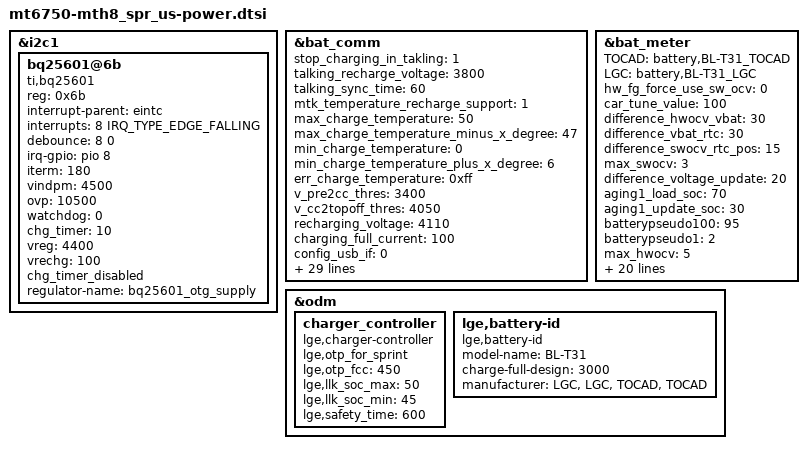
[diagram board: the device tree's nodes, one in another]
/*
 * LG Electronics TH8 power device tree source
 *
 * Copyright (c) 2017 LG Electronics Co., Ltd.
 *              http://www.lge.com
 *
 */

#include "../battery-BL-T31.dtsi"

/* Power */
&i2c1 {
	bq25601@6b {
		status = "okay";
		compatible = "ti,bq25601";
		reg = <0x6b>;

		interrupt-parent = <&eintc>;
		interrupts = <8 IRQ_TYPE_EDGE_FALLING>;
		debounce = <8 0>;
		irq-gpio = <&pio 8 0x2002>;

		iterm = <180>;
		vindpm = <4500>;
		ovp = <10500>;
		watchdog = <0>;
		chg_timer = <10>;
		vreg = <4400>;
		vrechg = <100>;

		chg_timer_disabled;

		regulator-name = "bq25601_otg_supply";
	};
};

&bat_comm {
	/* cust_charging.h */
	/* stop charging while in talking mode */
	stop_charging_in_takling = <1 >;
	talking_recharge_voltage = <3800 >;
	talking_sync_time = <60 >;

	/* Battery Temperature Protection */
	mtk_temperature_recharge_support = <1 >;
	max_charge_temperature = <50 >;
	max_charge_temperature_minus_x_degree = <47 >;
	min_charge_temperature = <0 >;
	min_charge_temperature_plus_x_degree = <6 >;
	err_charge_temperature = <0xff >;

	/* Linear Charging Threshold */
	v_pre2cc_thres = <3400 >;	/* unit: mV */
	v_cc2topoff_thres = <4050 >;
	recharging_voltage = <4110 >;
	charging_full_current = <100 >;	/* unit: mA */

	/* Charging Current Setting */
	config_usb_if = <0 >;
	usb_charger_current_suspend = <0 >;	/* Unit: 0.01 mA */
	usb_charger_current_unconfigured = <7000 >;	/* Unit: 0.01 mA */
	usb_charger_current_configured = <50000 >;	/* Unit: 0.01 mA */
	usb_charger_current = <50000 >;	/* Unit: 0.01 mA */
	ac_charger_current = <210000 >;	/* Unit: 0.01 mA */
	ac_charger_input_current = <120000 >;	/* Unit: 0.01 mA */
	non_std_ac_charger_current = <50000 >;	/* Unit: 0.01 mA */
	charging_host_charger_current = <150000 >;	/* Unit: 0.01 mA */
	apple_0_5a_charger_current = <50000 >;	/* Unit: 0.01 mA */
	apple_1_0a_charger_current = <100000 >;	/* Unit: 0.01 mA */
	apple_2_1a_charger_current = <210000 >;	/* Unit: 0.01 mA */

	/* charger error check */
	bat_low_temp_protect_enable = <0 >;
	v_charger_enable = <0 >;	/* 1:on , 0:off */
	v_charger_max = <6500 >;	/* unit: mV */
	v_charger_min = <4400 >;

	/*  Tracking TIME */
	onehundred_percent_tracking_time = <10 >;	/* Unit: second */
	npercent_tracking_time = <20 >;	/* Unit: second */
	sync_to_real_tracking_time = <60 >;	/* Unit: second */
	v_0percent_tracking = <3450 >;	/* Unit: mV */

	/* High battery support */
	high_battery_voltage_support = <1 >;

	mtk_pump_express_plus_support = <0 >;
	ta_start_battery_soc = <1 >;
	ta_stop_battery_soc = <85 >;
	ta_ac_charging_current = <320000 >;

	ta_ac_12v_input_current = <320000 >;
	ta_ac_9v_input_current = <320000 >;
	ta_ac_7v_input_current = <320000 >;

	ta_9v_support = <1 >;
	ta_12v_support = <1 >;
};

&bat_meter {
	TOCAD = "battery,BL-T31_TOCAD";
	LGC = "battery,BL-T31_LGC";

	/* cust_battery_meter.h */
	hw_fg_force_use_sw_ocv = <0 >;

	car_tune_value = <100 >;

	/* HW Fuel gague 2.0*/
	difference_hwocv_vbat = <30>;
	difference_vbat_rtc = <30>;
	difference_swocv_rtc_pos = <15>;

	max_swocv = <3>;

	difference_voltage_update = <20>;
	aging1_load_soc = <70>;
	aging1_update_soc = <30>;
	batterypseudo100 = <95>;
	batterypseudo1 = <2>;

	/* SW Fuel Gauge */
	max_hwocv = <5 >;
	max_vbat = <90 >;

	/* HW Fuel gague 1.0*/
	cust_poweron_delta_capacity_tolrance = <40 >;
	cust_poweron_low_capacity_tolrance = <5 >;
	cust_poweron_max_vbat_tolrance = <90 >;
	cust_poweron_delta_vbat_tolrance = <30 >;
	cust_poweron_delta_hw_sw_ocv_capacity_tolrance = <10 >;

	init_soc_by_sw_soc = <1 >;
	sync_ui_soc_imm =<0>;
	mtk_enable_aging_algorithm = <1>;
	md_sleep_current_check = <1>;
	q_max_by_current = <0>;

	/* SOC track to SWOCV */
	cust_tracking_gap = <15 >;	/* start tracking gap */
	cust_trackingoffset = <0 >;	/* force offset to shift soc to 0 */
	cust_trackingen = <0 >;	/* 0:disable, 1:enable */

	/* keep min uisoc until voltage less than customization voltage of min uisoc */
	cust_min_uisoc_percentage = <0 >;
	cust_min_uisoc_voltage = <3400 >;

	rbat_pull_up_r = <82000 >;
	rbat_pull_up_volt = <1800 >;

	embedded_battery =<1 >;
};

&odm {
	charger_controller: charger_controller {
		status = "ok";
		compatible = "lge,charger-controller";

		lge,otp_for_sprint;
		lge,otp_fcc = <450>;

		lge,llk_soc_max = <50>;
		lge,llk_soc_min = <45>;

		lge,safety_time = <600>; /*min*/
	};

	lge,battery-id {
		compatible = "lge,battery-id";

		model-name = "BL-T31";
		charge-full-design = <3000>;

		/* Auth ID - Vendor */
		manufacturer =
			"LGC", "LGC",
			"TOCAD", "TOCAD";
	};
};

